# ATtiny1634 register map
Vendor: Atmel; File version: 1.0
CPU: other r0p0, little endian, no MPU, no FPU, 4 interrupt priority bits
Registers are 8-bit, read-write, reset 0x0 unless marked. A register's access mark holds for its fields unless they carry their own. Offsets are from the block's base; [hi:lo] are bit positions; {n}, {i} and the like mark numbered series; 'fields as' and 'values as' point back to an identical list.

## CPU — CPU Registers
Base 0x00800034
{0x0+i} GPIOR{i} (i=0..2) — General Purpose I/O Register {i}
0x1B CCP — Configuration Change Protection
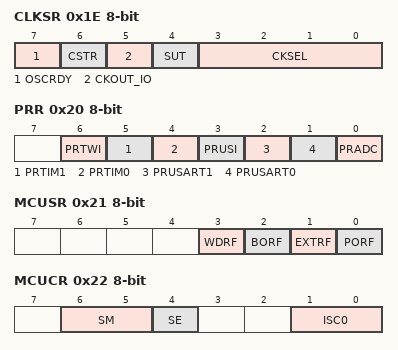
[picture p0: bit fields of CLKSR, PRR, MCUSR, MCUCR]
0x1E CLKSR — Clock Setting Register
  [7] OSCRDY — Oscillator Ready
  [6] CSTR — Clock Switch Trigger
  [5] CKOUT_IO — Clock Output (active low)
  [4] SUT — Start-up Time
  [3:0] CKSEL — Clock Select Bits
0x1F CLKPR — Clock Prescale Register
  [3:0] CLKPS — Clock Prescaler Select Bits
    0=1; 1=2; 2=4; 3=8; 4=16; 5=32; 6=64; 7=128; 8=256
0x20 PRR — Power Reduction Register
  [6] PRTWI — Power Reduction TWI
  [5] PRTIM1 — Power Reduction Timer/Counter1
  [4] PRTIM0 — Power Reduction Timer/Counter0
  [3] PRUSI — Power Reduction USI
  [2] PRUSART1 — Power Reduction USART1
  [1] PRUSART0 — Power Reduction USART0
  [0] PRADC — Power Reduction ADC
0x21 MCUSR — MCU Status Register
  [3] WDRF — Watchdog Reset Flag
  [2] BORF — Brown-out Reset Flag
  [1] EXTRF — External Reset Flag
  [0] PORF — Power-on reset flag
0x22 MCUCR — MCU Control Register
  [6:5] SM — Sleep Mode Select Bits
    0=IDLE; 1=ADC (ADC Noise Reduction (If Available)); 2=PDOWN (Power Down); 3=STDBY (Standby)
  [4] SE — Sleep Enable
  [1:0] ISC0 — Interrupt Sense Control 0 bits
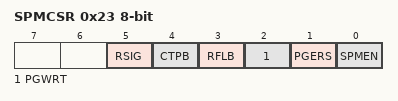
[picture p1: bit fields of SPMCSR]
0x23 SPMCSR — Store Program Memory Control and Status Register (read-only for debugger)
  [5] RSIG — Read Device Signature Imprint Table
  [4] CTPB — Clear Temporary Page Buffer
  [3] RFLB — Read Fuse and Lock Bits
  [2] PGWRT — Page Write
  [1] PGERS — Page Erase
  [0] SPMEN — Store program Memory Enable
0x2F OSCCAL0 — Oscillator Calibration Value (read-only for debugger)
0x30 OSCTCAL0A
0x31 OSCTCAL0B
0x32 OSCCAL1

## EEPROM
Base 0x0080003C
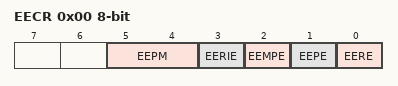
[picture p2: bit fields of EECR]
0x00 EECR — EEPROM Control Register
  [5:4] EEPM — EEPROM Programming Mode Bits
    0=ERASE_AND_WRITE_IN_ONE_OPERATION; 1=ERASE_ONLY; 2=WRITE_ONLY
  [3] EERIE — EEProm Ready Interrupt Enable
  [2] EEMPE — EEPROM Master Write Enable
  [1] EEPE — EEPROM Write Enable
  [0] EERE — EEPROM Read Enable
0x01 EEDR — EEPROM Data Register
0x02 EEAR 16-bit (reset mask 0xFF) — EEPROM Read/Write Access

## EXINT — External Interrupts
Base 0x00800047
0x00 PCMSK0 — Pin Change Mask Register 0
  [7:0] PCINT — Pin Change Enable Masks
0x01 PCMSK1 — Pin Change Mask Register 1
  [3:0] PCINT — Pin Change Enable Masks
0x02 PCMSK2 — Pin Change Mask Register 2
  [5:0] PCINT — Pin Change Enable Masks
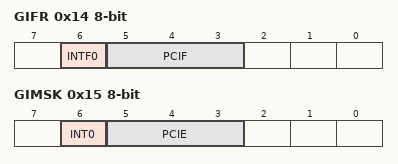
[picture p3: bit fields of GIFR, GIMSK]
0x14 GIFR — General Interrupt Flag Register
  [6] INTF0 — External Interrupt Flag 0
  [5:3] PCIF — Pin Change Interrupt Flags
0x15 GIMSK — General Interrupt Mask Register
  [6] INT0 — External Interrupt Request 0 Enable
  [5:3] PCIE — Pin Change Interrupt Enables

## FUSE — Fuses
Base 0x00800000
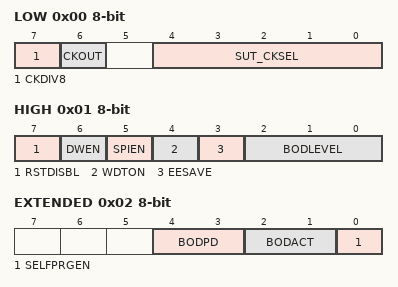
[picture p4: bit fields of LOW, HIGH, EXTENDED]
0x00 LOW
  [7] CKDIV8 — Divide clock by 8 internally
  [6] CKOUT — Clock output on PORTC2
  [4:0] SUT_CKSEL — Select Clock Source
    0=EXTCLK_6CK_16CK_16MS (Ext. Clock; Start-up time PWRDWN/RESET: 6 CK/16 CK + 16 ms); 2=INTRCOSC_8MHZ_6CK_16CK_16MS (Int. RC Osc. 8 MHz; Start-up time PWRDWN/RESET: 6 CK/16 CK + 16 ms); 4=INTULPOSC_32KHZ_6CK_16CK_16MS (Int. ULP Osc. 32 kHz; Start-up time PWRDWN/RESET: 6 CK/16 CK + 16 ms); 8=EXTCRES_0MHZ4_0MHZ9_258CK_16CK_16MS (Ext. Ceramic Res. 0.4-0.9 MHz; Start-up time PWRDWN/RESET: 258 CK/16 CK + 16 ms); 9=EXTXOSC_0MHZ4_0MHZ9_16KCK_16CK_16MS (Ext. Crystal Osc. 0.4-0.9 MHz; Start-up time PWRDWN/RESET: 16 K CK/16 CK + 16 ms); 10=EXTCRES_0MHZ9_3MHZ_258CK_16CK_16MS (Ext. Ceramic Res. 0.9-3.0 MHz; Start-up time PWRDWN/RESET: 258 CK/16 CK + 16 ms); 11=EXTXOSC_0MHZ9_3MHZ_16KCK_16CK_16MS (Ext. Crystal Osc. 0.9-3.0 MHz; Start-up time PWRDWN/RESET: 16 K CK/16 CK + 16 ms); 12=EXTCRES_3MHZ_8MHZ_258CK_16CK_16MS (Ext. Ceramic Res. 3.0-8.0 MHz; Start-up time PWRDWN/RESET: 258 CK/16 CK + 16 ms); 13=EXTXOSC_3MHZ_8MHZ_16KCK_16CK_16MS (Ext. Crystal Osc. 3.0-8.0 MHz; Start-up time PWRDWN/RESET: 16 K CK/16 CK + 16 ms); 14=EXTCRES_8MHZ_XX_258CK_16CK_16MS (Ext. Ceramic Res. 8.0- MHz; Start-up time PWRDWN/RESET: 258 CK/16 CK + 16 ms); 15=EXTXOSC_8MHZ_XX_16KCK_16CK_16MS (Ext. Crystal Osc. 8.0- MHz; Start-up time PWRDWN/RESET: 16 K CK/16 CK + 16 ms); 24=EXTCRES_0MHZ4_0MHZ9_1KCK_16CK_16MS (Ext. Ceramic Res. 0.4-0.9 MHz; Start-up time PWRDWN/RESET: 1K CK/16 CK + 16 ms); 26=EXTCRES_0MHZ9_3MHZ_1KCK_16CK_16MS (Ext. Ceramic Res. 0.9-3.0 MHz; Start-up time PWRDWN/RESET: 1K CK/16 CK + 16 ms); 28=EXTCRES_3MHZ_8MHZ_1KCK_16CK_16MS (Ext. Ceramic Res. 3.0-8.0 MHz; Start-up time PWRDWN/RESET: 1K CK/16 CK + 16 ms); 30=EXTCRES_8MHZ_XX_1KCK_16CK_16MS (Ext. Ceramic Res. 8.0- MHz; Start-up time PWRDWN/RESET: 1K CK/16 CK + 16 ms)
0x01 HIGH
  [7] RSTDISBL — Reset Disabled (Enable PC2 as i/o pin)
  [6] DWEN — Debug Wire enable
  [5] SPIEN — Serial program downloading (SPI) enabled
  [4] WDTON — Watch-dog Timer always on
  [3] EESAVE — Preserve EEPROM through the Chip Erase cycle
  [2:0] BODLEVEL — Brown-out Detector trigger level
    4=4V3 (Brown-out detection at VCC=4.3 V); 5=2V7 (Brown-out detection at VCC=2.7 V); 6=1V8 (Brown-out detection at VCC=1.8 V)
0x02 EXTENDED
  [4:3] BODPD — BOD mode of operation when the device is in sleep mode
    1=BOD_SAMPLED (Sampled); 2=BOD_ENABLED (Enabled); 3=BOD_DISABLED (Disabled)
  [2:1] BODACT — BOD mode of operation when the device is active or idle
    values as BODPD
  [0] SELFPRGEN — Self Programming enable
